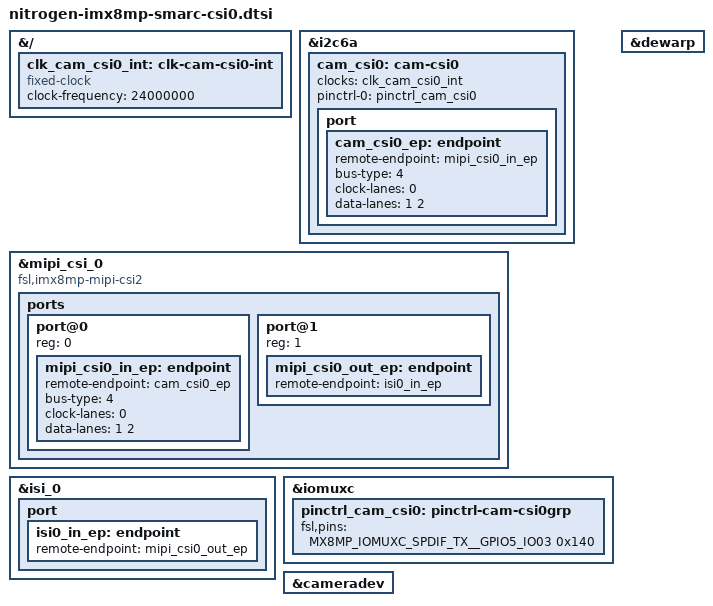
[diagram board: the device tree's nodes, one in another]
// SPDX-License-Identifier: (GPL-2.0+ OR MIT)
/*
 * Copyright 2026 Ezurio LLC
 */

#include <dt-bindings/gpio/gpio.h>

#include "imx8mp-pinfunc.h"

&{/} {
	clk_cam_csi0_int: clk-cam-csi0-int {
		compatible = "fixed-clock";
		#clock-cells = <0>;
		clock-frequency = <24000000>;
	};
};

&i2c6a {
	#address-cells = <1>;
	#size-cells = <0>;

	cam_csi0: cam-csi0 {
		clocks = <&clk_cam_csi0_int>; /* On Camera module */
		clock-names = "xclk";

		pinctrl-names = "default";
		pinctrl-0 = <&pinctrl_cam_csi0>;

		port {
			cam_csi0_ep: endpoint {
				remote-endpoint = <&mipi_csi0_in_ep>;
				bus-type = <4>;
				clock-lanes = <0>;
				data-lanes = <1 2>;
			};
		};
	};
};

&mipi_csi_0 {
	compatible = "fsl,imx8mp-mipi-csi2", "fsl,imx8mp-mipi-csi2";
	status = "okay";

	ports {
		#address-cells = <1>;
		#size-cells = <0>;

		port@0 {
			reg = <0>;

			mipi_csi0_in_ep: endpoint {
				remote-endpoint = <&cam_csi0_ep>;
				bus-type = <4>;
				clock-lanes = <0>;
				data-lanes = <1 2>;
			};
		};

		port@1 {
			reg = <1>;

			mipi_csi0_out_ep: endpoint {
				remote-endpoint = <&isi0_in_ep>;
			};
		};
	};
};

&isi_0 {
	status = "okay";

	port {
		isi0_in_ep: endpoint {
			remote-endpoint = <&mipi_csi0_out_ep>;
		};
	};
};

&iomuxc {
	pinctrl_cam_csi0: pinctrl-cam-csi0grp {
		fsl,pins = <
			MX8MP_IOMUXC_SPDIF_TX__GPIO5_IO03	0x140
		>;
	};
};

&dewarp {
	status = "okay";
};

&cameradev {
	status = "okay";
};
